AUTOSAR XML (schema 4-0-3)
standard types defined: uint8, Boolean, UInt16, UInt32, UInt8
package /AUTOSAR_Platform/DataConstrs
  range DC_Boolean: raw 0..1
  range DC_UInt16: raw 0..65535
  range DC_UInt8: raw 0..255
package /PATAC/Facility/DataTypes/Implementation
  compu method COMPU_Boolean: 0=FALSE, 1=TRUE
  unit NoUnit: factor-si-to-unit=1, offset-si-to-unit=0
package /PATAC/MSM/ComponentTypes
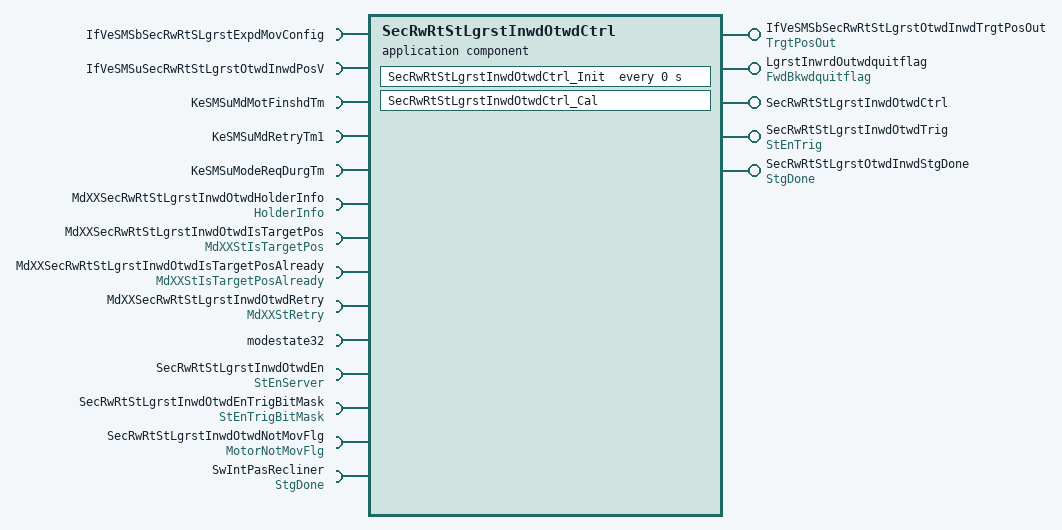
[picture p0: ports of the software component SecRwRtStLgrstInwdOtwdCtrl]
  application sw component type SecRwRtStLgrstInwdOtwdCtrl
    5 x provide port:
      IfVeSMSbSecRwRtStLgrstOtwdInwdTrgtPosOut: nonqueued-sender-com-spec{data-element=TrgtPosOut/Val, init-value=0}, provided-interface=TrgtPosOut
      LgrstInwrdOutwdquitflag: nonqueued-sender-com-spec{data-element=FwdBkwdquitflag/Val, init-value=0}, provided-interface=FwdBkwdquitflag
      SecRwRtStLgrstInwdOtwdCtrl: server-com-spec{operation=Cal, queue-length=1}, provided-interface=SecRwRtStLgrstInwdOtwdCtrl
      SecRwRtStLgrstInwdOtwdTrig: nonqueued-sender-com-spec{data-element=StEnTrig/Val, init-value=0}, provided-interface=StEnTrig
      SecRwRtStLgrstOtwdInwdStgDone: nonqueued-sender-com-spec{data-element=StgDone/Val, init-value=0}, provided-interface=StgDone
    14 x require port:
      IfVeSMSbSecRwRtSLgrstExpdMovConfig: nonqueued-receiver-com-spec{data-element=IfVeSMSbSecRwRtSLgrstExpdMovConfig/Val, filter=data-filter-type=ALWAYS, init-value=0}, required-interface=IfVeSMSbSecRwRtSLgrstExpdMovConfig
      IfVeSMSuSecRwRtStLgrstOtwdInwdPosV: nonqueued-receiver-com-spec{data-element=IfVeSMSuSecRwRtStLgrstOtwdInwdPosV/Val, filter=data-filter-type=ALWAYS, init-value=0}, required-interface=IfVeSMSuSecRwRtStLgrstOtwdInwdPosV
      KeSMSuMdMotFinshdTm: parameter-require-com-spec{init-value=0, parameter=KeSMSuMdMotFinshdTm/Val}, required-interface=KeSMSuMdMotFinshdTm
      KeSMSuMdRetryTm1: parameter-require-com-spec{init-value=0, parameter=KeSMSuMdRetryTm1/Val}, required-interface=KeSMSuMdRetryTm1
      KeSMSuModeReqDurgTm: parameter-require-com-spec{init-value=0, parameter=KeSMSuModeReqDurgTm/Val}, required-interface=KeSMSuModeReqDurgTm
      MdXXSecRwRtStLgrstInwdOtwdHolderInfo: nonqueued-receiver-com-spec{data-element=HolderInfo/Val, filter=data-filter-type=ALWAYS, init-value=0}, required-interface=HolderInfo
      MdXXSecRwRtStLgrstInwdOtwdIsTargetPos: nonqueued-receiver-com-spec{data-element=MdXXStIsTargetPos/Val, filter=data-filter-type=ALWAYS, init-value=0}, required-interface=MdXXStIsTargetPos
      MdXXSecRwRtStLgrstInwdOtwdIsTargetPosAlready: nonqueued-receiver-com-spec{data-element=MdXXStIsTargetPosAlready/Val, filter=data-filter-type=ALWAYS, init-value=0}, required-interface=MdXXStIsTargetPosAlready
      MdXXSecRwRtStLgrstInwdOtwdRetry: nonqueued-receiver-com-spec{data-element=MdXXStRetry/Val, filter=data-filter-type=ALWAYS, init-value=0}, required-interface=MdXXStRetry
      modestate32: nonqueued-receiver-com-spec{data-element=modestate32/Val, filter=data-filter-type=ALWAYS, init-value=0}, required-interface=modestate32
      SecRwRtStLgrstInwdOtwdEn: required-com-specs=[Clear, Get, Set], required-interface=StEnServer
      SecRwRtStLgrstInwdOtwdEnTrigBitMask: nonqueued-receiver-com-spec{data-element=StEnTrigBitMask/Val, filter=data-filter-type=ALWAYS, init-value=0}, required-interface=StEnTrigBitMask
      SecRwRtStLgrstInwdOtwdNotMovFlg: nonqueued-receiver-com-spec{data-element=MotorNotMovFlg/Val, filter=data-filter-type=ALWAYS, init-value=0}, required-interface=MotorNotMovFlg
      SwIntPasRecliner: nonqueued-receiver-com-spec{data-element=StgDone/Val, filter=data-filter-type=ALWAYS, init-value=0}, required-interface=StgDone
    behavior SecRwRtStLgrstInwdOtwdCtrl_InternalBehavior
      operation invoked event OIT_SecRwRtStLgrstInwdOtwdCtrl_Cal_SecRwRtStLgrstInwdOtwdCtrl_Cal: start-on-event=SecRwRtStLgrstInwdOtwdCtrl_Cal, operation=SecRwRtStLgrstInwdOtwdCtrl.Cal
      timing event SecRwRtStLgrstInwdOtwdCtrl_InitEvent: start-on-event=SecRwRtStLgrstInwdOtwdCtrl_Init, period=0
      runnable SecRwRtStLgrstInwdOtwdCtrl_Cal
        data-receive-point-by-arguments:
          10 x access:
            REC_IfVeSMSbSecRwRtSLgrstExpdMovConfig_Val: accessed-variable=IfVeSMSbSecRwRtSLgrstExpdMovConfig.Val
            REC_IfVeSMSuSecRwRtStLgrstOtwdInwdPosV_Val: accessed-variable=IfVeSMSuSecRwRtStLgrstOtwdInwdPosV.Val
            REC_MdXXSecRwRtStLgrstInwdOtwdHolderInfo_Val: accessed-variable=MdXXSecRwRtStLgrstInwdOtwdHolderInfo.Val
            REC_MdXXSecRwRtStLgrstInwdOtwdIsTargetPos_Val: accessed-variable=MdXXSecRwRtStLgrstInwdOtwdIsTargetPos.Val
            REC_MdXXSecRwRtStLgrstInwdOtwdIsTargetPosAlready_Val: accessed-variable=MdXXSecRwRtStLgrstInwdOtwdIsTargetPosAlready.Val
            REC_MdXXSecRwRtStLgrstInwdOtwdRetry_Val: accessed-variable=MdXXSecRwRtStLgrstInwdOtwdRetry.Val
            REC_modestate32_Val: accessed-variable=modestate32.Val
            REC_SecRwRtStLgrstInwdOtwdEnTrigBitMask_Val: accessed-variable=SecRwRtStLgrstInwdOtwdEnTrigBitMask.Val
            REC_SecRwRtStLgrstInwdOtwdNotMovFlg_Val: accessed-variable=SecRwRtStLgrstInwdOtwdNotMovFlg.Val
            REC_SwIntPasRecliner_Val: accessed-variable=SwIntPasRecliner.Val
        data-send-points:
          4 x access:
            SEND_IfVeSMSbSecRwRtStLgrstOtwdInwdTrgtPosOut_Val: accessed-variable=IfVeSMSbSecRwRtStLgrstOtwdInwdTrgtPosOut.Val
            SEND_LgrstInwrdOutwdquitflag_Val: accessed-variable=LgrstInwrdOutwdquitflag.Val
            SEND_SecRwRtStLgrstInwdOtwdTrig_Val: accessed-variable=SecRwRtStLgrstInwdOtwdTrig.Val
            SEND_SecRwRtStLgrstOtwdInwdStgDone_Val: accessed-variable=SecRwRtStLgrstOtwdInwdStgDone.Val
        parameter access PA_KeSMSuMdMotFinshdTm_Val: accessed-parameter=KeSMSuMdMotFinshdTm.Val
        parameter access PA_KeSMSuMdRetryTm1_Val: accessed-parameter=KeSMSuMdRetryTm1.Val
        parameter access PA_KeSMSuModeReqDurgTm_Val: accessed-parameter=KeSMSuModeReqDurgTm.Val
        sync call SC_SecRwRtStLgrstInwdOtwdEn_Get: operation=SecRwRtStLgrstInwdOtwdEn.Get, timeout=0
      runnable SecRwRtStLgrstInwdOtwdCtrl_Init
        parameter access PA_KeSMSuMdMotFinshdTm_Val: accessed-parameter=KeSMSuMdMotFinshdTm.Val
        parameter access PA_KeSMSuMdRetryTm1_Val: accessed-parameter=KeSMSuMdRetryTm1.Val
        parameter access PA_KeSMSuModeReqDurgTm_Val: accessed-parameter=KeSMSuModeReqDurgTm.Val
  swc implementation SecRwRtStLgrstInwdOtwdCtrl_Implementation: behavior=SecRwRtStLgrstInwdOtwdCtrl_InternalBehavior
    code-descriptors:
      code Default: artifact-descriptors=autosar-engineering-object={short-label=Default, category=SWSRC}
package /PATAC/MSM/ModeAdjust/CalPortInterface
  parameter interface KeSMSuMdMotFinshdTm
    parameter data prototype Val: sw-calibration-access=READ-WRITE, type=UInt16
  parameter interface KeSMSuModeReqDurgTm
    parameter data prototype Val: sw-calibration-access=READ-WRITE, type=UInt16
package /PATAC/MSM/ModeAdjust/PortInterface
  client server interface SecRwRtStLgrstInwdOtwdCtrl
    operation Cal
  client server interface StEnServer
    operation Clear
      arg data: type=UInt8, direction=IN, server-argument-impl-policy=USE-ARGUMENT-TYPE
    operation Get
      arg data: type=UInt32, direction=OUT, server-argument-impl-policy=USE-ARGUMENT-TYPE
    operation Set
      arg data: type=UInt8, direction=IN, server-argument-impl-policy=USE-ARGUMENT-TYPE
  12 x sender receiver interface:
    FwdBkwdquitflag: invalidation-policy{data-element=FwdBkwdquitflag/Val, handle-invalid=DONT-INVALIDATE}
      data Val: type=Boolean
    HolderInfo: invalidation-policy{data-element=HolderInfo/Val, handle-invalid=DONT-INVALIDATE}
      data Val: type=UInt32
    IfVeSMSbSecRwRtSLgrstExpdMovConfig: invalidation-policy{data-element=IfVeSMSbSecRwRtSLgrstExpdMovConfig/Val, handle-invalid=DONT-INVALIDATE}
      data Val: type=Boolean
    MdXXStIsTargetPos: invalidation-policy{data-element=MdXXStIsTargetPos/Val, handle-invalid=DONT-INVALIDATE}
      data Val: type=UInt32
    MdXXStIsTargetPosAlready: invalidation-policy{data-element=MdXXStIsTargetPosAlready/Val, handle-invalid=DONT-INVALIDATE}
      data Val: type=UInt32
    MdXXStRetry: invalidation-policy{data-element=MdXXStRetry/Val, handle-invalid=DONT-INVALIDATE}
      data Val: type=UInt32
    modestate32: invalidation-policy{data-element=modestate32/Val, handle-invalid=DONT-INVALIDATE}
      data Val: type=UInt32
    MotorNotMovFlg: invalidation-policy{data-element=MotorNotMovFlg/Val, handle-invalid=DONT-INVALIDATE}
      data Val: type=Boolean
    StEnTrig: invalidation-policy{data-element=StEnTrig/Val, handle-invalid=DONT-INVALIDATE}
      data Val: type=Boolean
    StEnTrigBitMask: invalidation-policy{data-element=StEnTrigBitMask/Val, handle-invalid=DONT-INVALIDATE}
      data Val: type=UInt32
    StgDone: invalidation-policy{data-element=StgDone/Val, handle-invalid=DONT-INVALIDATE}
      data Val: type=Boolean
    TrgtPosOut: invalidation-policy{data-element=TrgtPosOut/Val, handle-invalid=DONT-INVALIDATE}
      data Val: type=Boolean
package /PATAC/MSM/PortInterfaces
  parameter interface KeSMSuMdRetryTm1
    parameter data prototype Val: sw-calibration-access=READ-WRITE, type=UInt8
  sender receiver interface IfVeSMSuSecRwRtStLgrstOtwdInwdPosV: invalidation-policy{data-element=IfVeSMSuSecRwRtStLgrstOtwdInwdPosV/Val, handle-invalid=DONT-INVALIDATE}
    data Val: type=Boolean
